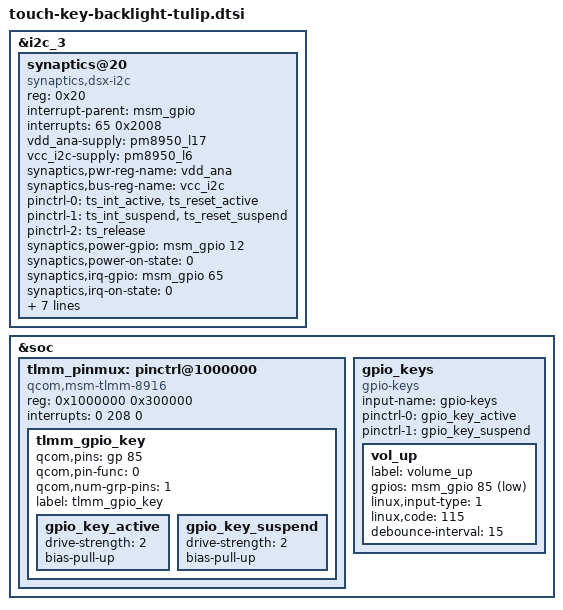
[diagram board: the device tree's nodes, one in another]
&i2c_3 { /* BLSP1 QUP3 */
		synaptics@20 {
			compatible = "synaptics,dsx-i2c";
			reg = <0x20>;
			interrupt-parent = <&msm_gpio>;
			interrupts = <65 0x2008>;
			vdd_ana-supply = <&pm8950_l17>;
			vcc_i2c-supply = <&pm8950_l6>;
			synaptics,pwr-reg-name = "vdd_ana";
			synaptics,bus-reg-name = "vcc_i2c";
					/* pins used by touchscreen */
			pinctrl-names = "pmx_ts_active","pmx_ts_suspend","pmx_ts_release";
			pinctrl-0 = <&ts_int_active &ts_reset_active>;
			pinctrl-1 = <&ts_int_suspend &ts_reset_suspend>;
			pinctrl-2 = <&ts_release>;
			synaptics,power-gpio = <&msm_gpio 12 0x00>;
			synaptics,power-on-state = <0>;
			synaptics,irq-gpio = <&msm_gpio 65 0x2008>;
			synaptics,irq-on-state = <0>;
			synaptics,irq-flags = <0x2008>; /* IRQF_ONESHOT | IRQF_TRIGGER_LOW */
			synaptics,reset-gpio = <&msm_gpio 64 0x00>;
			synaptics,power-delay-ms = <200>;
			synaptics,reset-delay-ms = <200>;
			synaptics,reset-active-ms = <10>;
			synaptics,reset-on-state = <0>;
			//synaptics,swap-axes;
			//synaptics,x-flip;
			//synaptics,y-flip;
			synaptics,cap-button-codes = <158 172 139>;
			//synaptics,max-y-for-2d = <800>; /* remove if no virtual buttons */
			//synaptics,vir-button-codes = <102 100 900 100 60 158 300 900 100 60>;
		};
	};

&soc {
	tlmm_pinmux: pinctrl@1000000 {
		compatible = "qcom,msm-tlmm-8916";
		reg = <0x1000000 0x300000>;
		interrupts = <0 208 0>;

		tlmm_gpio_key {
			qcom,pins = <&gp 85>;
			qcom,pin-func = <0>;
			qcom,num-grp-pins = <1>;
			label = "tlmm_gpio_key";
			gpio_key_active: gpio_key_active {
				drive-strength = <2>;
				bias-pull-up;
			};
			gpio_key_suspend: gpio_key_suspend {
				drive-strength = <2>;
				bias-pull-up;
			};
		};
	};

	gpio_keys {
		compatible = "gpio-keys";
		input-name = "gpio-keys";
		pinctrl-names = "tlmm_gpio_key_active","tlmm_gpio_key_suspend";
		pinctrl-0 = <&gpio_key_active>;
		pinctrl-1 = <&gpio_key_suspend>;

		vol_up {
			label = "volume_up";
			gpios = <&msm_gpio 85 0x1>;
			linux,input-type = <1>;
			linux,code = <115>;
			debounce-interval = <15>;
		};
	};
};
